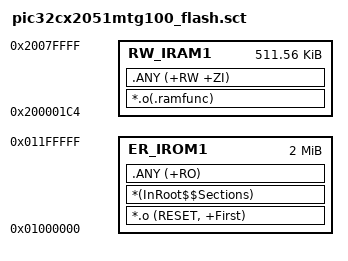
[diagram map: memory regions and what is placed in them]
#! armcc -E
; *************************************************************
; *** Scatter-Loading Description File generated by uVision ***
; *************************************************************

#if !defined(MBED_APP_START)
  #define MBED_APP_START 0x01000000
#endif

#if !defined(MBED_APP_SIZE)
  #define MBED_APP_SIZE 0x200000
#endif

#if !defined(MBED_CONF_TARGET_BOOT_STACK_SIZE)
  #define MBED_CONF_TARGET_BOOT_STACK_SIZE 0x400
#endif

#if !defined(MBED_VECTOR_TBL_SIZE)
  #define MBED_VECTOR_TBL_SIZE 0x01c4
#endif

#if !defined(MBED_RAM_START)
  #define MBED_RAM_START 0x20000000
#endif

#if !defined(MBED_RAM_SIZE)
  #define MBED_RAM_SIZE 0x80000
#endif

#define Stack_Size MBED_CONF_TARGET_BOOT_STACK_SIZE

LR_IROM1 MBED_APP_START MBED_APP_SIZE  {    ; load region size_region
  ER_IROM1 MBED_APP_START MBED_APP_SIZE  {  ; load address = execution address
   *.o (RESET, +First)
   *(InRoot$$Sections)
   .ANY (+RO)
  }
  RW_IRAM1 (MBED_RAM_START + MBED_VECTOR_TBL_SIZE) (MBED_RAM_SIZE - MBED_VECTOR_TBL_SIZE)  {  ; RW data
   *.o(.ramfunc)
   .ANY (+RW +ZI)
  }
}

